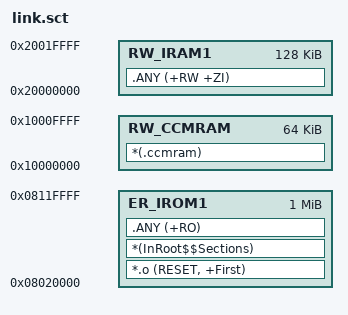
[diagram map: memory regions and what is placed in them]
; *************************************************************
; *** Scatter-Loading Description File generated by uVision ***
; *** 增加CCMRAM支持 - 64KB (0x10000000-0x1000FFFF)      ***
; *************************************************************

LR_IROM1 0x08020000 0x00100000  {    ; load region size_region
  ER_IROM1 0x08020000 0x00100000  {  ; load address = execution address
   *.o (RESET, +First)
   *(InRoot$$Sections)
   .ANY (+RO)
  }
  
  RW_IRAM1 0x20000000 0x00020000  {  ; 主RAM区域 (128KB)
   .ANY (+RW +ZI)
  }
  
  RW_CCMRAM 0x10000000 0x00010000  { ; CCMRAM区域 (64KB)
   *(.ccmram)                      ; 显式分配到CCMRAM的段
  }
}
